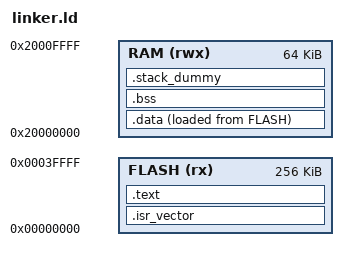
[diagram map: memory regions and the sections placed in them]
ENTRY(Reset_Handler)

MEMORY
{
    FLASH (rx)  : ORIGIN = 0x00000000, LENGTH = 256K
    RAM   (rwx) : ORIGIN = 0x20000000, LENGTH = 64K
}

__stack_size = DEFINED(__stack_size) ? __stack_size : 4K;
_estack = ORIGIN(RAM) + LENGTH(RAM);

SECTIONS
{
    .isr_vector :
    {
        KEEP(*(.isr_vector))
    } > FLASH

    .text :
    {
        *(.text)
        *(.text*)
        *(.rodata)
        *(.rodata*)
        KEEP(*(.init))
        KEEP(*(.fini))
    } > FLASH

    .data :
    {
        _sdata = .;
        *(.data*)
        _edata = .;
    } > RAM AT > FLASH

    _sidata = LOADADDR(.data);

    .bss :
    {
        _sbss = .;
        *(.bss*)
        *(COMMON)
        _ebss = .;
    } > RAM

    . = ALIGN(8);
    _heap_start = .;

    .stack_dummy :
    {
        . = . + __stack_size;
    } > RAM
    . = ALIGN(8);

    _heap_end = ORIGIN(RAM) + LENGTH(RAM) - __stack_size;
}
